# PN74xxAU register map
File version: 2
The PN74xxAU is an ARM Cortex-M0 based NFC and Smart card controller for embedded application featuring a high level of integration and low power consumption. PN74xxAU builds NFC contactless frontend & ISO7816 contact interface for PC readers, Access control and POS terminals. Flash memory is fully available for the application designer to implement application specific software. It support Unique host interface options i.e USB, I2C, SPI, UART, TDA8026 AUX interface. IC has also I2C and SPI master interfaces allowing integration of LCD display, SD card, PACE crypto accelerator, Multi slot SAM support using a TDA 8026 etc. $Id: PN74xxAU.svd 17917 2016-02-16 10:25:44Z Purnank G (ing05193) $ $Date: 2016-02-16 15:55:44 +0530 (Tue, 16 Feb 2016) $ $Revision: 17917 $ This XML File is generated for these peripherals: |========== | ========== | ========= | ===================================| |Peripheral | Base Add | Interrupt | Description | |========== | ========== | ========= | ===================================| | Timer | 0x4001C000 | 0 | General purpose timer 0/1/2/3 | | CLIF | 0x40004000 | 2 | Contactless Interface Frontend | | EECTRL | 0x00200000 | 3 | EEPROM and Flash Controller | | HostIf | 0x40020000 | 6 | Host Interface | | USB | 0x40028000 | - | Universal Serial Bus | | CT | 0x40014000 | 7 | Contact Interface | | PMU | 0x40008000 | 9 | Power Management Unit | | SPIM | 0x40034000 | 10 | SPI Master | | I2CM | 0x40030000 | 11 | I2C Master | | PCR | 0x40024000 | 12 | Power Co
CPU: CM0 r0p0, little endian, no MPU, no FPU, 2 interrupt priority bits
Registers are 32-bit, read-write, reset 0x0 unless marked. A register's access mark holds for its fields unless they carry their own. Offsets are from the block's base; lines under a group give offsets from that group; [hi:lo] are bit positions; {n}, {i} and the like mark numbered series; 'fields as' and 'values as' point back to an identical list; <NAME> marks a mode.

## Memory map
0x00200000 EECTRL size 0x1000 — EEPROM and Flash Controller
0x40004000 CLIF size 0x4000 — Contactless Interface Frontend
0x40008000 PMU size 0x4000 — Power Management Unit
0x4000C000 CRC size 0x4000 — Cyclic Redunduncy Check
0x40010000 ClockGen size 0x4000
0x40014000 CT size 0x4000 — Contact Interface
0x40018000 RNG size 0x4000 — Random Number Generator
0x4001C000 Timer size 0x4000 — General purpose timer 0/1/2/3
0x40020000 HostIf size 0x4000 — Host Interface
0x40024000 PCR size 0x4000 — Power Control and Reset
0x40028000 USB size 0x4000 — Universal Serial Bus
0x40030000 I2CM size 0x4000 — I2C Master
0x40034000 SPIM size 0x4000 — SPI Master

## Interrupts
0 Timer_ISR (Timer) — General purpose timer 0/1/2/3 Interrupt
2 CLIF_ISR (CLIF) — Contactless Interface Frontend Interrupt
3 EECTRL_ISR (EECTRL) — EEPROM and Flash Controller Interrupt
6 HostIf_ISR (HostIf) — Host Interface Interrupt
7 CT_ISR (CT) — Contact Interface Interrupt
9 PMU_ISR (PMU) — Power Management Unit Interrupt
10 SPIM_ISR (SPIM) — SPI Master Interrupt
11 I2CM_ISR (I2CM) — I2C Master Interrupt
12 PCR_ISR (PCR) — Power Control and Reset Interrupt
13 GPIO_Common (PCR) — Common intetrrupt for ALL GPIOs
{n+13} GPIO_{n:02} (PCR) (n=1..12) — Intetrrupt for GPIO {n}

## CRC — Cyclic Redunduncy Check
Base 0x4000C000
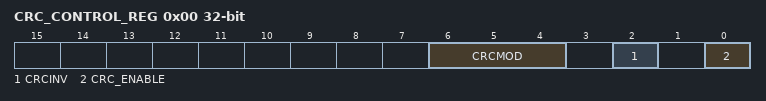
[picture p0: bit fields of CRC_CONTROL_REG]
0x00 CRC_CONTROL_REG — control register
  [6:4] CRCMOD — CRC mode of computation
  [2] CRCINV — Invert input data
  [0] CRC_ENABLE — enable crc
0x04 CRC_DAT32_REG — data 32 register
  [31:0] CRCDAT32 — 32 bits CRC value
0x08 CRC_DAT16_REG — data 16 register
  [15:0] CRCDAT16 — 16 bits CRC value
0x0C CRC_DAT8_REG — data 8 register
  [7:0] CRCDAT8 — 8 bits CRC value
0x10 CRC_DAT_CALC_REG ro reset 0xFFFF — crc computed register
  [31:0] CRCDAT_COMPUTED — 32 bits CRC computed value
0x14 CRC_DAT_PRELOAD_REG — preload register
  [31:0] CRCDAT_PRELOAD — 32 bits CRC preload value

## RNG — Random Number Generator
Base 0x40018000
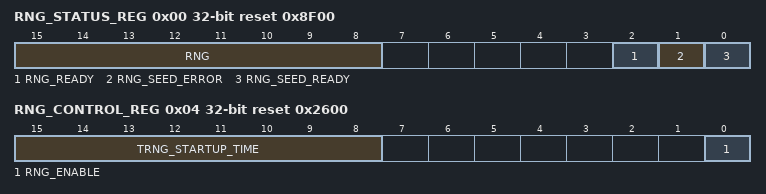
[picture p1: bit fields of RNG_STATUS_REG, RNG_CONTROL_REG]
0x00 RNG_STATUS_REG ro reset 0x8F00 — status register
  [15:8] RNG — RNG number
  [2] RNG_READY — high if a new random value is available for read
  [1] RNG_SEED_ERROR — high if TRNG timeout reached. Indicates an error in seeding process.
  [0] RNG_SEED_READY — high if seed process is done and RNG is running, generating a new data every cycle.
0x04 RNG_CONTROL_REG reset 0x2600 — control register
  [15:8] TRNG_STARTUP_TIME — trng startup time to bypass TRNG seed
  [0] RNG_ENABLE — enable RNG, used for gating main clock
